VERSION "1.0"

NS_ :

BS_:

BU_:

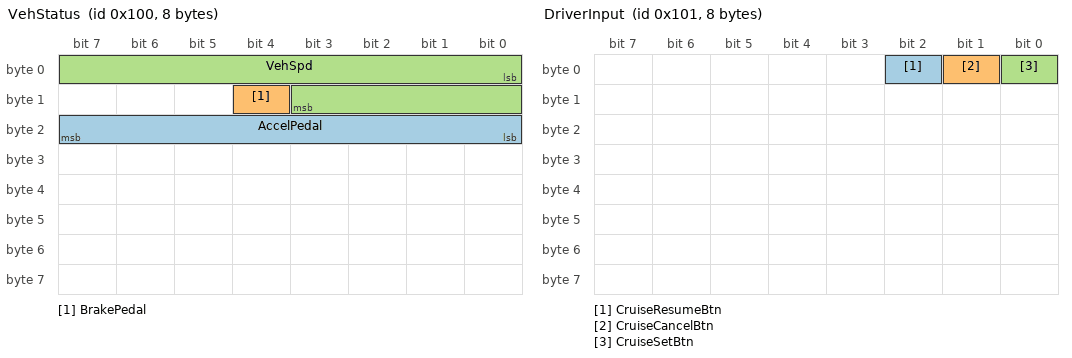
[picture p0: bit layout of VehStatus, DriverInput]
BO_ 256 VehStatus: 8 BCM
 SG_ AccelPedal : 16|8@1+ (1,0) [0|100] "%" Vector__XXX
 SG_ BrakePedal : 12|1@1+ (1,0) [0|1] "" Vector__XXX
 SG_ VehSpd : 0|12@1+ (0.1,0.0) [0|300] "km/h" Vector__XXX

BO_ 257 DriverInput: 8 BCM
 SG_ CruiseResumeBtn : 2|1@1+ (1,0) [0|1] "" Vector__XXX
 SG_ CruiseCancelBtn : 1|1@1+ (1,0) [0|1] "" Vector__XXX
 SG_ CruiseSetBtn : 0|1@1+ (1,0) [0|1] "" Vector__XXX

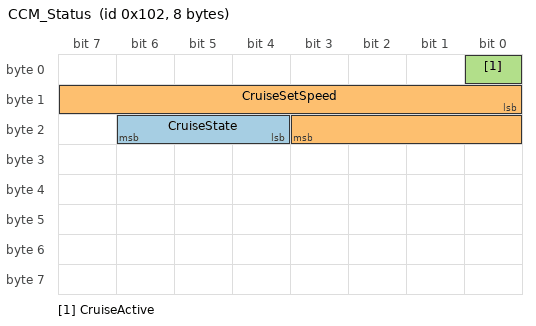
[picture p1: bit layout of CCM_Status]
BO_ 258 CCM_Status: 8 CCM
 SG_ CruiseState : 20|3@1+ (1,0) [0|3] "" Vector__XXX
 SG_ CruiseSetSpeed : 8|12@1+ (0.1,0.0) [0|300] "km/h" Vector__XXX
 SG_ CruiseActive : 0|1@1+ (1,0) [0|1] "" Vector__XXX

BO_ 512 MotorStatus: 8 MCU
 SG_ MotorSpeed : 8|16@1+ (1,0) [0|20000] "rpm" Vector__XXX
 SG_ MotorTemp : 0|8@1+ (1.0,-40.0) [-40|215] "degC" Vector__XXX

BA_DEF_ BO_  "GenMsgCycleTime" INT 0 65535;
BA_DEF_DEF_  "GenMsgCycleTime" 0;
BA_ "GenMsgCycleTime" BO_ 256 20;
BA_ "GenMsgCycleTime" BO_ 257 20;
BA_ "GenMsgCycleTime" BO_ 258 20;
BA_ "GenMsgCycleTime" BO_ 512 20;
VAL_ 258 CruiseState 0 "IDLE" 1 "ARMED" 2 "ACTIVE" 3 "CANCEL" ;
